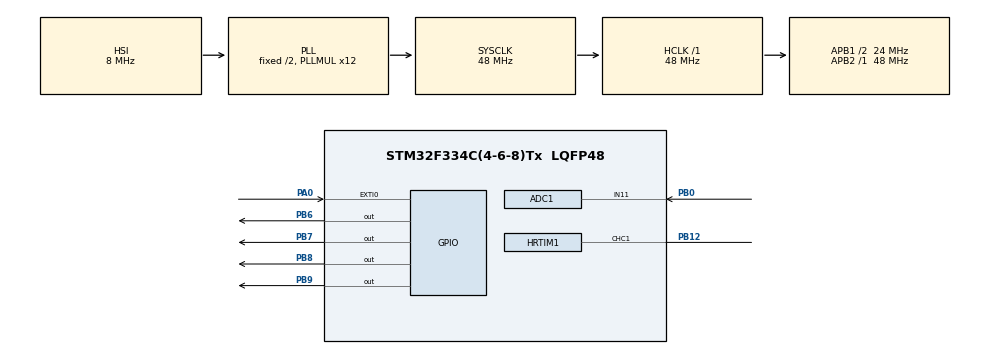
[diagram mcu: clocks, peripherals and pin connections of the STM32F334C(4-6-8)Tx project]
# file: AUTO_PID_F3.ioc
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Mcu.Family=STM32F3
Dma.ADC1.0.Instance=DMA1_Channel1
RCC.CortexFreq_Value=48000000
ADC1.Rank-0\#ChannelRegularConversion=1
ADC1.ContinuousConvMode=ENABLE
ADC1.OffsetNumber-0\#ChannelRegularConversion=ADC_OFFSET_NONE
RCC.SYSCLKSourceVirtual=RCC_SYSCLKSOURCE_PLLCLK
NVIC.TIM7_DAC2_IRQn=true\:0\:1\:false\:false\:true\:true\:true
RCC.APB1CLKDivider=RCC_HCLK_DIV2
HRTIM1.PWMChannel_TC1=HRTIM_OUTPUT_TC1
ProjectManager.StackSize=0x400
VP_TIM7_VS_ClockSourceINT.Mode=Enable_Timer
HRTIM1.PrescalerRatio_TC=HRTIM_PRESCALERRATIO_DIV1
Dma.ADC1.0.PeriphDataAlignment=DMA_PDATAALIGN_HALFWORD
ProjectManager.TargetToolchain=TrueSTUDIO
Dma.ADC1.0.Mode=DMA_CIRCULAR
ADC1.Offset-0\#ChannelRegularConversion=0
RCC.HCLKFreq_Value=48000000
Dma.ADC1.0.Priority=DMA_PRIORITY_LOW
RCC.APB2TimFreq_Value=48000000
PB6.Signal=GPIO_Output
Dma.ADC1.0.Direction=DMA_PERIPH_TO_MEMORY
TIM7.Period=191
ADC1.SubFamily=STM32F334x8
RCC.LSE_VALUE=32768
Dma.ADC1.0.MemDataAlignment=DMA_MDATAALIGN_HALFWORD
RCC.AHBFreq_Value=48000000
HRTIM1.PWMPulse_TC1=170
ADC1.Channel-0\#ChannelRegularConversion=ADC_CHANNEL_11
RCC.HSE_VALUE=8000000
PB0.Mode=IN11-Single-Ended
board=custom
RCC.PLLMUL=RCC_PLL_MUL12
HRTIM1.CompareUnit1-Output_TC1=HRTIM_COMPAREUNIT_1
RCC.APB2Freq_Value=48000000
Dma.ADC1.0.PeriphInc=DMA_PINC_DISABLE
PB7.Signal=GPIO_Output
ADC1.DMAContinuousRequests=ENABLE
Mcu.Name=STM32F334C(4-6-8)Tx
ADC1.SamplingTime-0\#ChannelRegularConversion=ADC_SAMPLETIME_19CYCLES_5
PA0.Signal=GPXTI0
NVIC.EXTI0_IRQn=true\:0\:3\:false\:false\:true\:true\:true
RCC.SYSCLKFreq_VALUE=48000000
PB9.Signal=GPIO_Output
Mcu.Package=LQFP48
PB12.Mode=Output_TC1
ADC1.master=1
ADC1.EnableInjectedConversion=DISABLE
HRTIM1.CompareValue1-Output_TC1=180
Dma.ADC1.0.MemInc=DMA_MINC_ENABLE
ProjectManager.HeapSize=0x200
RCC.HSI_VALUE=8000000
NVIC.PriorityGroup=NVIC_PRIORITYGROUP_2
ADC1.NbrOfConversionFlag=1
RCC.APB1TimFreq_Value=48000000
PB8.Signal=GPIO_Output
NVIC.DMA1_Channel1_IRQn=true\:0\:2\:false\:false\:true\:false\:true
HRTIM1.Configuration_TC=Waveform
Dma.Request0=ADC1
RCC.APB1Freq_Value=24000000
PB0.Signal=ADC1_IN11
HRTIM1.Periode_TC=191
PB12.Signal=HRTIM1_CHC1

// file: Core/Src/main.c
/* USER CODE BEGIN Header */
/**
  ******************************************************************************
  * @file           : main.c
  * @brief          : Main program body
  ******************************************************************************
  * @attention
  *
  * <h2><center>&copy; Copyright (c) 2020 STMicroelectronics.
  * All rights reserved.</center></h2>
  *
  * This software component is licensed by ST under BSD 3-Clause license,
  * the "License"; You may not use this file except in compliance with the
  * License. You may obtain a copy of the License at:
  *                        opensource.org/licenses/BSD-3-Clause
  *
  ******************************************************************************
  */
/* USER CODE END Header */

#include "main.h"
#include "adc.h"
#include "dma.h"
#include "hrtim.h"
#include "tim.h"
#include "gpio.h"

/* USER CODE BEGIN PV */
  extern uint16_t I_out_TAB[IOUT_SIZE_TD];

/* USER CODE END PV */

void SystemClock_Config(void);

int main(void)
{

  /* MCU Configuration--------------------------------------------------------*/

  /* Reset of all peripherals, Initializes the Flash interface and the Systick. */
  HAL_Init();

  /* Configure the system clock */
  SystemClock_Config();

  /* Initialize all configured peripherals */
  MX_GPIO_Init();
  MX_DMA_Init();
  MX_ADC1_Init();
  MX_HRTIM1_Init();
  MX_TIM7_Init();
  /* USER CODE BEGIN 2 */
  //start ADC DMA
  HAL_ADC_Start_DMA(&hadc1,(uint32_t*)I_out_TAB,IOUT_SIZE_TD);

  HAL_Delay(1);
//start TIM7 for creating time base to  compute PI, START HRTIM_OUTPUT_TC1 to generate PWM with  10%duty
HAL_HRTIM_WaveformOutputStart(&hhrtim1, HRTIM_OUTPUT_TC1);
HAL_HRTIM_WaveformCountStart(&hhrtim1, HRTIM_TIMERID_TIMER_C);
HAL_TIM_Base_Start_IT(&htim7);

//usedfor test

  /* USER CODE END 2 */

  /* Infinite loop */
  while (1)
  {

  }
}

void SystemClock_Config(void)
{
  RCC_OscInitTypeDef RCC_OscInitStruct = {0};
  RCC_ClkInitTypeDef RCC_ClkInitStruct = {0};
  RCC_PeriphCLKInitTypeDef PeriphClkInit = {0};

  /** Initializes the CPU, AHB and APB busses clocks
  */
  RCC_OscInitStruct.OscillatorType = RCC_OSCILLATORTYPE_HSI;
  RCC_OscInitStruct.HSIState = RCC_HSI_ON;
  RCC_OscInitStruct.HSICalibrationValue = RCC_HSICALIBRATION_DEFAULT;
  RCC_OscInitStruct.PLL.PLLState = RCC_PLL_ON;
  RCC_OscInitStruct.PLL.PLLSource = RCC_PLLSOURCE_HSI;
  RCC_OscInitStruct.PLL.PLLMUL = RCC_PLL_MUL12;
  if (HAL_RCC_OscConfig(&RCC_OscInitStruct) != HAL_OK)
  {
    Error_Handler();
  }
  /** Initializes the CPU, AHB and APB busses clocks
  */
  RCC_ClkInitStruct.ClockType = RCC_CLOCKTYPE_HCLK|RCC_CLOCKTYPE_SYSCLK
                              |RCC_CLOCKTYPE_PCLK1|RCC_CLOCKTYPE_PCLK2;
  RCC_ClkInitStruct.SYSCLKSource = RCC_SYSCLKSOURCE_PLLCLK;
  RCC_ClkInitStruct.AHBCLKDivider = RCC_SYSCLK_DIV1;
  RCC_ClkInitStruct.APB1CLKDivider = RCC_HCLK_DIV2;
  RCC_ClkInitStruct.APB2CLKDivider = RCC_HCLK_DIV1;

  if (HAL_RCC_ClockConfig(&RCC_ClkInitStruct, FLASH_LATENCY_1) != HAL_OK)
  {
    Error_Handler();
  }
  PeriphClkInit.PeriphClockSelection = RCC_PERIPHCLK_HRTIM1|RCC_PERIPHCLK_ADC12;
  PeriphClkInit.Adc12ClockSelection = RCC_ADC12PLLCLK_DIV1;
  PeriphClkInit.Hrtim1ClockSelection = RCC_HRTIM1CLK_HCLK;
  if (HAL_RCCEx_PeriphCLKConfig(&PeriphClkInit) != HAL_OK)
  {
    Error_Handler();
  }
}

void Error_Handler(void)
{
}

/************************ (C) COPYRIGHT STMicroelectronics *****END OF FILE****/
